# STM32G061 register map
File version: 1.4
CPU: CM0 r0p1, little endian, MPU, no FPU, 2 interrupt priority bits
Registers are 32-bit, read-write, reset 0x0 unless marked. A register's access mark holds for its fields unless they carry their own. Offsets are from the block's base; lines under a group give offsets from that group; [hi:lo] are bit positions; {n}, {i} and the like mark numbered series; 'fields as' and 'values as' point back to an identical list; <NAME> marks a mode.

## Memory map
0x40000000 TIM2 size 0x400 — General-purpose-timers
0x40000400 TIM3 size 0x400 — General-purpose-timers
0x40001000 TIM6 size 0x400 — Basic timers
0x40001400 TIM7 size 0x400
0x40002000 TIM14 size 0x400 — General purpose timers
0x40002800 RTC size 0x400 — Real-time clock
0x40002C00 WWDG size 0x400 — System window watchdog
0x40003000 IWDG size 0x400 — Independent watchdog
0x40003800 SPI2
0x40004400 USART2 size 0x400
0x40005400 I2C1 size 0x400 — Inter-integrated circuit
0x40005800 I2C2 size 0x400
0x40007000 PWR size 0x400 — Power control
0x40007400 DAC size 0x400
0x40007800 HDMI_CEC size 0x400
0x40007C00 LPTIM1 size 0x400 — Low power timer
0x40008000 LPUART1 size 0x400 — Low-power universal asynchronous receiver transmitter
0x40009400 LPTIM2 size 0x400
0x4000B000 TAMP size 0x400 — Tamper and backup registers
0x40010000 SYSCFG size 0x100 — System configuration controller
0x40010030 VREFBUF size 0x400 — System configuration controller
0x40012400 ADC size 0x400 — ADC address block description
0x40012C00 TIM1 size 0x400 — Advanced-timers
0x40013000 SPI1 size 0x400 — Serial peripheral interface
0x40013800 USART1 size 0x400 — Universal synchronous asynchronous receiver transmitter
0x40014000 TIM15 size 0x400 — General purpose timers
0x40014400 TIM16 size 0x400 — General purpose timers
0x40014800 TIM17 size 0x400
0x40015800 DBG size 0x400 — Debug support
0x40020000 DMA1 size 0x400 — DMA controller
0x40020800 DMAMUX size 0x800
0x40021000 RCC size 0x400 — Reset and clock control
0x40021800 EXTI size 0x400 — External interrupt/event controller
0x40022000 FLASH size 0x400
0x40023000 CRC size 0x400 — Cyclic redundancy check calculation unit
0x40025000 RNG size 0x400 — Random number generator
0x40026000 AES size 0x400 — AES register block
0x50000000 GPIOA size 0x400 — General-purpose I/Os
0x50000400 GPIOB size 0x400 — General-purpose I/Os
0x50000800 GPIOC size 0x400
0x50000C00 GPIOD size 0x400
0x50001000 GPIOE size 0x400
0x50001400 GPIOF size 0x400

## Interrupts
0 WWDG — Window watchdog interrupt
1 PVD (EXTI, PWR) — Power voltage detector interrupt
2 RTC_TAMP (RTC) — RTC and TAMP interrupts
3 FLASH — Flash global interrupt
4 RCC — RCC global interrupt
5 EXTI0_1 (EXTI) — EXTI line 0 & 1 interrupt
6 EXTI2_3 (EXTI) — EXTI line 2 & 3 interrupt
7 EXTI4_15 (EXTI) — EXTI line 4 to 15 interrupt
9 DMA1_Channel1 (DMA1) — DMA channel 1 interrupt
10 DMA1_Channel2_3 (DMA1) — DMA channel 2 and 3 interrupts
11 DMA1_Channel4_5_6_7_DMAMUX (DMA1) — interrupts for DMA1 channels 4-7 and DMAMUX
13 TIM1_BRK_UP_TRG_COM (TIM1) — TIM1 break, update, trigger and commutation interrupts
14 TIM1_CC (TIM1) — TIM1 Capture Compare interrupt
15 TIM2 — TIM2 global interrupt
16 TIM3 — TIM3 global interrupt
17 TIM6_DAC_LPTIM1 (DAC) — TIM6, LPTIM1 and DAC global interrupt
18 TIM7 — TIM7 + LPTIM2 global interrupt
19 TIM14 — TIM14 global interrupt
20 TIM15 — Timer 15 global interrupt
21 TIM16 — TIM16 global interrupt
22 TIM17 — TIM17 global interrupt
23 I2C1 — I2C1 global interrupt
24 I2C2 — I2C2 global interrupt
25 SPI1 — SPI1 gloabl interrupt
26 SPI2_SPI3 (SPI2) — SPI2 gloabl interrupt
27 USART1 — USART1 global interrupt
28 USART2 — USART2 global interrupt
30 CEC (HDMI_CEC) — CEC global interrupt
31 AES_RNG (AES) — AES and RNG global interrupts

## CRC — Cyclic redundancy check calculation unit
Base 0x40023000
0x00 DR reset 0xFFFFFFFF — Data register
  [31:0] DR — Data register bits
0x00 DR8 8-bit reset 0xFF (alternate view of DR) — Data register - byte sized
  [7:0] DR8 — Data register bits
0x00 DR16 16-bit reset 0xFFFF (alternate view of DR) — Data register - half-word sized
  [15:0] DR16 — Data register bits
0x04 IDR — Independent data register
  [31:0] IDR — General-purpose 32-bit data register bits
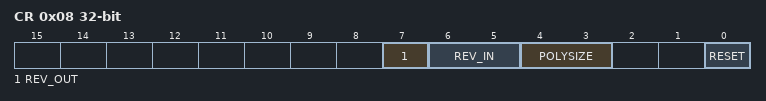
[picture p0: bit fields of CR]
0x08 CR access per field — Control register
  [7] REV_OUT rw — Reverse output data This bit controls the reversal of the bit order of the output data.
    0=Normal (Bit order not affected); 1=Reversed (Bit reversed output)
  [6:5] REV_IN rw — Reverse input data These bits control the reversal of the bit order of the input data
    0=Normal (Bit order not affected); 1=Byte (Bit reversal done by byte); 2=HalfWord (Bit reversal done by half-word); 3=Word (Bit reversal done by word)
  [4:3] POLYSIZE rw — Polynomial size These bits control the size of the polynomial.
    0=32-bit polynomial; 1=16-bit polynomial; 2=8-bit polynomial; 3=7-bit polynomial
  [0] RESET wo — RESET bit
    1=Resets the CRC calculation unit and sets the data register to 0xFFFF FFFF
0x10 INIT reset 0xFFFFFFFF — Initial CRC value
  [31:0] INIT — Programmable initial CRC value
0x14 POL reset 0x4C11DB7 — polynomial
  [31:0] POL — Programmable polynomial
